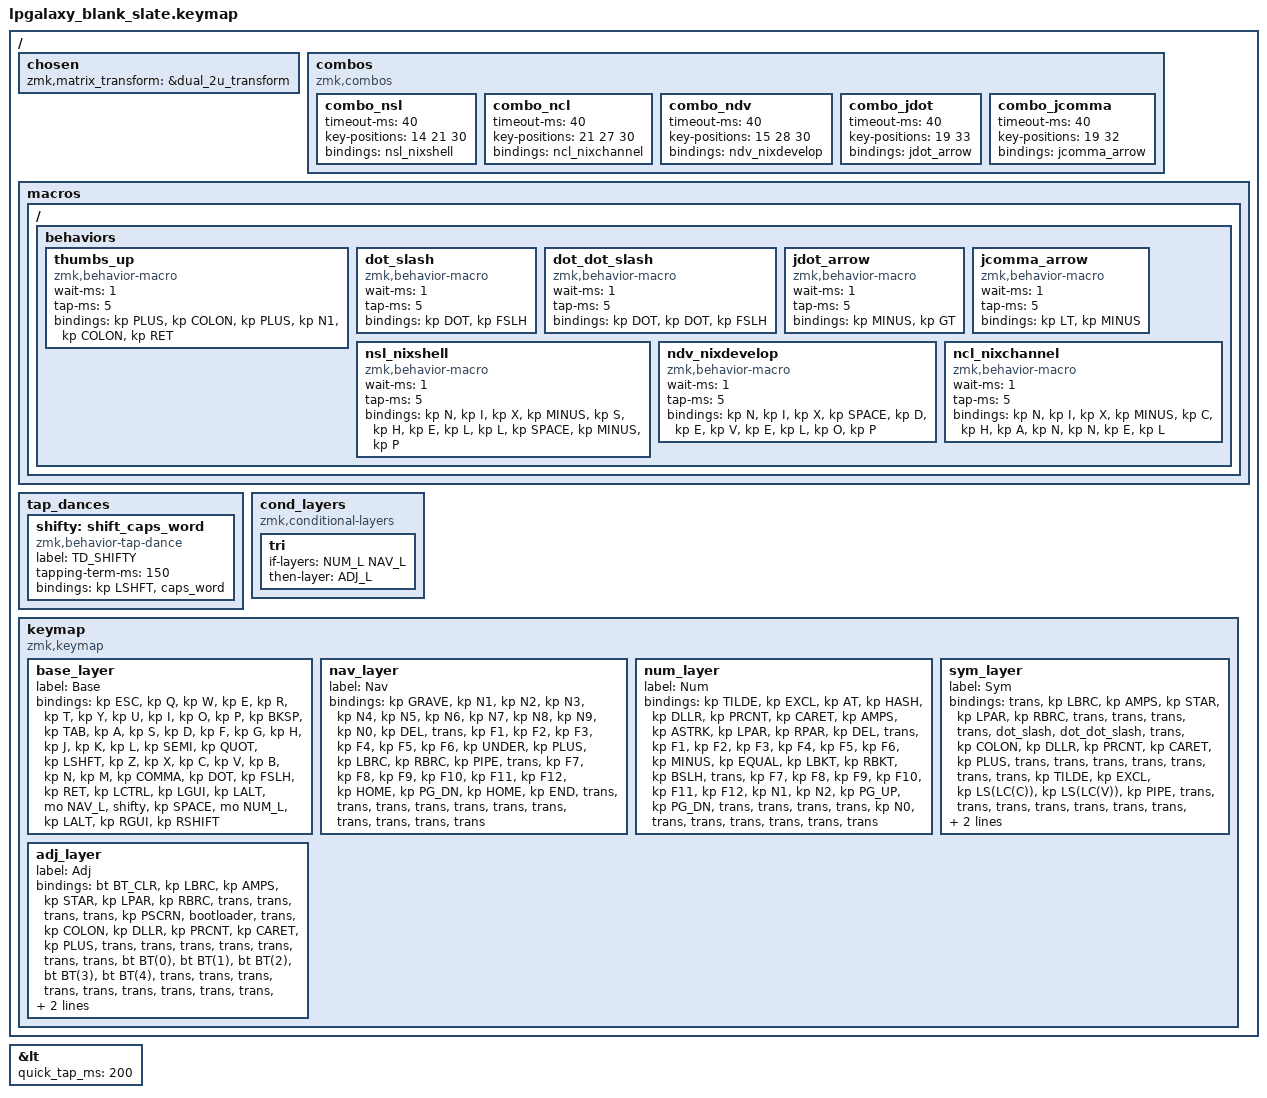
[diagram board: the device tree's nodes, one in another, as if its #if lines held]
/*
 * Copyright (c) 2022 Pete Johanson
 *
 * SPDX-License-Identifier: MIT
 */

#include <behaviors.dtsi>
#include <dt-bindings/zmk/keys.h>
#include <dt-bindings/zmk/bt.h>
#include <dt-bindings/zmk/outputs.h>

#define QWERTY_BASE 1

// #define TBLE_ORTHO   1
#define TBLE_MIT     1
// #define TBLE_DUAL_2U 1

#define NAV_L 1
#define NUM_L 2
#define SYM_L 3
#define ADJ_L 4

// Using layer taps on thumbs, having quick tap as well helps w/ repeating space/backspace
&lt { quick_tap_ms = <200>; };

#define BT(n) BT_SEL n

/ {
    chosen {
       zmk,matrix_transform =
#ifdef TBLE_DUAL_2U
                       &dual_2u_transform;
#elif defined(TBLE_MIT)
                       &mit_transform;
#else
                       &ortho_transform;
#endif
    };

    combos {
        compatible = "zmk,combos";
        combo_nsl {
            timeout-ms = <40>;
            key-positions = <14 21 30>;
            bindings = <&nsl_nixshell>;
        };
        combo_ncl {
            timeout-ms = <40>;
            key-positions = <21 27 30>;
            bindings = <&ncl_nixchannel>;
        };
        combo_ndv {
            timeout-ms = <40>;
            key-positions = <15 28 30>;
            bindings = <&ndv_nixdevelop>;
        };
        combo_jdot {
            timeout-ms = <40>;
            key-positions = <19 33>;
            bindings = <&jdot_arrow>;
        };
        combo_jcomma {
            timeout-ms = <40>;
            key-positions = <19 32>;
            bindings = <&jcomma_arrow>;
        };
    };

    macros {
      ZMK_MACRO(thumbs_up,
		wait-ms = <1>;
		tap-ms = <5>;
                bindings = <&kp PLUS &kp COLON &kp PLUS &kp N1 &kp COLON &kp RET>;
		)
      ZMK_MACRO(dot_slash,
        wait-ms = <1>;
        tap-ms = <5>;
        bindings = <&kp DOT &kp FSLH>;
      )
      ZMK_MACRO(dot_dot_slash,
        wait-ms = <1>;
        tap-ms = <5>;
        bindings = <&kp DOT &kp DOT &kp FSLH>;
      )
      ZMK_MACRO(jdot_arrow,
        wait-ms = <1>;
        tap-ms = <5>;
        bindings = <&kp MINUS &kp GT>;
      )
      ZMK_MACRO(jcomma_arrow,
        wait-ms = <1>;
        tap-ms = <5>;
        bindings = <&kp LT &kp MINUS>;
      )
      ZMK_MACRO(nsl_nixshell,
        wait-ms = <1>;
        tap-ms = <5>;
        bindings = <&kp N &kp I &kp X
        &kp MINUS &kp S &kp H &kp E &kp L &kp L
        &kp SPACE &kp MINUS &kp P>;
      )
      ZMK_MACRO(ndv_nixdevelop,
        wait-ms = <1>;
        tap-ms = <5>;
        bindings = <&kp N &kp I &kp X
        &kp SPACE &kp D &kp E &kp V &kp E &kp L
        &kp O &kp P>;
      )
      ZMK_MACRO(ncl_nixchannel,
        wait-ms = <1>;
        tap-ms = <5>;
        bindings = <&kp N &kp I &kp X
        &kp MINUS &kp C &kp H &kp A &kp N &kp N
        &kp E &kp L>;
      )
    };
    
    tap_dances {
    	shifty: shift_caps_word {
		compatible = "zmk,behavior-tap-dance";
		label = "TD_SHIFTY";
		#binding-cells = <0>;
		tapping-term-ms = <150>;
		bindings = <&kp LSHFT>, <&caps_word>;
	};
    };

// Conditional layer only when we have less thumb keys

    cond_layers {
        compatible = "zmk,conditional-layers";
	tri {
	    if-layers = <NUM_L NAV_L>;
	    then-layer = <ADJ_L>;
        };
    };


    keymap {
        compatible = "zmk,keymap";

        base_layer {
            label = "Base";
            bindings = <
#ifdef QWERTY_BASE
 &kp ESC    &kp Q      &kp W      &kp E       &kp R          &kp T          &kp Y            &kp U          &kp I       &kp O      &kp P         &kp BKSP
 &kp TAB    &kp A      &kp S      &kp D       &kp F          &kp G          &kp H            &kp J          &kp K       &kp L      &kp SEMI      &kp QUOT
 &kp LSHFT  &kp Z      &kp X      &kp C       &kp V          &kp B          &kp N            &kp M          &kp COMMA   &kp DOT    &kp FSLH      &kp RET
#else
 &kp ESC    &kp Q      &kp W      &kp F       &kp P          &kp B          &kp J            &kp L          &kp U       &kp Y      &kp QUOT      &kp BKSP
 &kp TAB    &kp A      &kp R      &kp S       &kp T          &kp G          &kp M            &kp N          &kp E       &kp I      &kp O         &kp QUOT
 &kp LSHFT  &kp Z      &kp X      &kp C       &kp D          &kp V          &kp K            &kp H          &kp COMMA   &kp DOT    &kp SEMI      &kp RET
#endif
#ifdef TBLE_DUAL_2U
 &kp LCTRL  &kp LGUI   &kp LALT   &mo NAV_L         &shifty                        &kp SPACE                &mo NUM_L   &kp LALT   &kp RGUI      &kp RSHIFT
#elif defined(TBLE_MIT)
 &mo SYM_L  &kp LCTRL   &kp LGUI  &kp LALT    &mo NAV_L          &kp SPACE                   &mo NUM_L      &kp LEFT    &kp DOWN   &kp UP        &kp RIGHT
#else
 &kp LCTRL  &mo SYM_L   &kp LGUI  &kp LALT    &mo NAV_L      &kp SPACE      &kp RET          &mo NUM_L      &kp LEFT    &kp UP     &kp DOWN      &kp RIGHT
#endif
            >;
        };

        nav_layer {
            label = "Nav";
            bindings = <
&kp GRAVE  &kp N1     &kp N2     &kp N3      &kp N4          &kp N5       &kp N6     &kp N7         &kp N8      &kp N9     &kp N0     &kp DEL
&trans     &kp F1     &kp F2     &kp F3      &kp F4          &kp F5       &kp F6     &kp UNDER      &kp PLUS    &kp LBRC   &kp RBRC   &kp PIPE
&trans     &kp F7     &kp F8     &kp F9      &kp F10         &kp F11      &kp F12    &kp HOME       &kp PG_DN   &kp HOME   &kp END    &trans
#ifdef TBLE_DUAL_2U
&trans  &trans        &trans     &trans              &trans                    &trans       &trans         &trans &trans &trans
#elif defined(TBLE_MIT)
&trans  &trans        &trans     &trans      &trans                &trans             &trans      &kp C_NEXT  &trans &trans &trans
#else
&trans  &trans        &trans     &trans      &trans          &trans       &trans    &trans  &trans         &trans &trans &trans
#endif
            >;
        };

        num_layer {
            label = "Num";
            bindings = <
&kp TILDE  &kp EXCL   &kp AT &kp HASH &kp DLLR  &kp PRCNT   &kp CARET     &kp AMPS   &kp ASTRK   &kp LPAR     &kp RPAR   &kp DEL
&trans     &kp F1     &kp F2 &kp F3   &kp F4    &kp F5      &kp F6        &kp MINUS  &kp EQUAL   &kp LBKT     &kp RBKT   &kp BSLH
&trans     &kp F7     &kp F8 &kp F9   &kp F10   &kp F11     &kp F12       &kp N1     &kp N2      &kp PG_UP    &kp PG_DN  &trans
#ifdef TBLE_DUAL_2U
&trans  &trans       &trans     &kp N0              &trans                 &trans            &trans         &trans &trans &trans
#elif defined(TBLE_MIT)
&trans  &trans       &trans     &trans      &trans           &none            &trans        &trans          &trans &trans &trans
#else
&trans  &trans       &trans     &kp N0      &trans    &none         &none     &kp ESC        &kp DEL      &trans &trans &trans
#endif
            >;
        };

        sym_layer {
            label = "Sym";
            bindings = <
&trans     &kp LBRC   &kp AMPS   &kp STAR    &kp LPAR     &kp RBRC     &trans     &trans    &trans       &trans       &dot_slash &dot_dot_slash
&trans     &kp COLON  &kp DLLR   &kp PRCNT   &kp CARET    &kp PLUS     &trans     &trans    &trans       &trans       &trans     &trans
&trans     &kp TILDE  &kp EXCL   &kp LS(LC(C)) &kp LS(LC(V)) &kp PIPE  &trans     &trans    &trans       &trans       &trans     &trans
#ifdef TBLE_DUAL_2U
&trans &trans        &trans     &kp RPAR                &trans                    &trans       &trans         &trans &trans &trans
#elif defined(TBLE_MIT)
&trans &trans        &trans     &kp RPAR        &trans                &trans             &trans      &trans   &trans &trans &trans
#else
&trans &trans        &trans     &kp RPAR        &trans          &trans       &trans    &trans  &trans         &trans &trans &trans
#endif
            >;
        };

        adj_layer {
            label = "Adj";
            bindings = <
&bt BT_CLR &kp LBRC   &kp AMPS   &kp STAR    &kp LPAR     &kp RBRC     &trans     &trans    &trans       &trans       &kp PSCRN  &bootloader
&trans     &kp COLON  &kp DLLR   &kp PRCNT   &kp CARET    &kp PLUS     &trans     &trans    &trans       &trans       &trans     &trans
&trans     &bt BT(0)  &bt BT(1)  &bt BT(2)   &bt BT(3)    &bt BT(4)    &trans     &trans    &trans       &trans       &trans     &trans
#ifdef TBLE_DUAL_2U
&trans &trans        &trans     &kp RPAR                &trans                    &trans       &trans         &trans &trans &trans
#elif defined(TBLE_MIT)
&trans &trans        &trans     &trans          &trans                &trans             &trans      &trans   &trans &trans &trans
#else
&trans &trans        &trans     &kp RPAR        &trans          &trans       &trans    &trans  &trans         &trans &trans &trans
#endif
            >;
        };


    };
};

